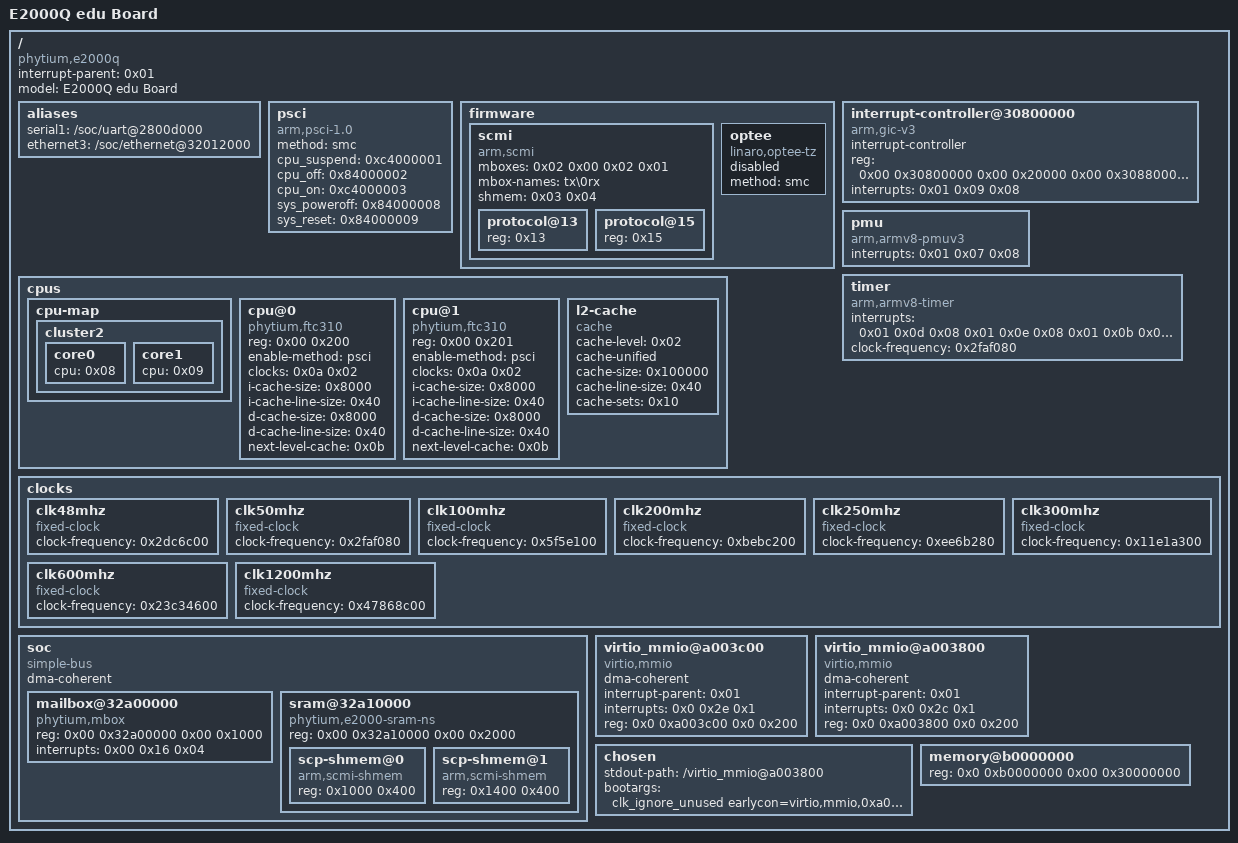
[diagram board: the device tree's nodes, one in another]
/dts-v1/;

/memreserve/	0x0000000080000000 0x0000000000010000;
/ {
	compatible = "phytium,e2000q";
	interrupt-parent = <0x01>;
	#address-cells = <0x02>;
	#size-cells = <0x02>;
	model = "E2000Q edu Board";

	aliases {
		serial1 = "/soc/uart@2800d000";
		ethernet3 = "/soc/ethernet@32012000";
	};

	psci {
		compatible = "arm,psci-1.0";
		method = "smc";
		cpu_suspend = <0xc4000001>;
		cpu_off = <0x84000002>;
		cpu_on = <0xc4000003>;
		sys_poweroff = <0x84000008>;
		sys_reset = <0x84000009>;
	};

	firmware {

		scmi {
			compatible = "arm,scmi";
			mboxes = <0x02 0x00 0x02 0x01>;
			mbox-names = "tx\0rx";
			shmem = <0x03 0x04>;
			#address-cells = <0x01>;
			#size-cells = <0x00>;

			protocol@13 {
				reg = <0x13>;
				#clock-cells = <0x01>;
				phandle = <0x0a>;
			};

			protocol@15 {
				reg = <0x15>;
				#thermal-sensor-cells = <0x01>;
				phandle = <0x05>;
			};
		};

		optee {
			compatible = "linaro,optee-tz";
			method = "smc";
			status = "disabled";
		};
	};

	cpus {
		#address-cells = <0x02>;
		#size-cells = <0x00>;

		cpu-map {

			// cluster0 {

			// 	core0 {
			// 		cpu = <0x06>;
			// 	};
			// };

			// cluster1 {

			// 	core0 {
			// 		cpu = <0x07>;
			// 	};
			// };

			cluster2 {

				core0 {
					cpu = <0x08>;
				};

				core1 {
					cpu = <0x09>;
				};
			};
		};
		// cpu@100 {
		// 	device_type = "cpu";
		// 	compatible = "phytium,ftc664\0arm,armv8";
		// 	reg = <0x00 0x00>;
		// 	enable-method = "psci";
		// 	clocks = <0x0a 0x00>;
		// 	i-cache-size = <0xc000>;
		// 	i-cache-line-size = <0x40>;
		// 	d-cache-size = <0x8000>;
		// 	d-cache-line-size = <0x40>;
		// 	next-level-cache = <0x0b>;
		// 	phandle = <0x06>;
		// };

		// cpu@101 {
		// 	device_type = "cpu";
		// 	compatible = "phytium,ftc664\0arm,armv8";
		// 	reg = <0x00 0x100>;
		// 	enable-method = "psci";
		// 	clocks = <0x0a 0x01>;
		// 	i-cache-size = <0xc000>;
		// 	i-cache-line-size = <0x40>;
		// 	d-cache-size = <0x8000>;
		// 	d-cache-line-size = <0x40>;
		// 	next-level-cache = <0x0b>;
		// 	phandle = <0x07>;
		// };
		cpu@0 {
			device_type = "cpu";
			compatible = "phytium,ftc310\0arm,armv8";
			reg = <0x00 0x200>;
			enable-method = "psci";
			clocks = <0x0a 0x02>;
			i-cache-size = <0x8000>;
			i-cache-line-size = <0x40>;
			d-cache-size = <0x8000>;
			d-cache-line-size = <0x40>;
			next-level-cache = <0x0b>;
			phandle = <0x08>;
		};
		cpu@1 {
			device_type = "cpu";
			compatible = "phytium,ftc310\0arm,armv8";
			reg = <0x00 0x201>;
			enable-method = "psci";
			clocks = <0x0a 0x02>;
			i-cache-size = <0x8000>;
			i-cache-line-size = <0x40>;
			d-cache-size = <0x8000>;
			d-cache-line-size = <0x40>;
			next-level-cache = <0x0b>;
			phandle = <0x09>;
		};

		l2-cache {
			compatible = "cache";
			cache-level = <0x02>;
			cache-unified;
			cache-size = <0x100000>;
			cache-line-size = <0x40>;
			cache-sets = <0x10>;
			phandle = <0x0b>;
		};
	};

	interrupt-controller@30800000 {
		compatible = "arm,gic-v3";
		#interrupt-cells = <0x03>;
		#address-cells = <0x02>;
		#size-cells = <0x02>;
		ranges;
		interrupt-controller;
		reg = <0x00 0x30800000 0x00 0x20000 0x00 0x30880000 0x00 0x80000 0x00 0x30840000 0x00 0x10000 0x00 0x30850000 0x00 0x10000 0x00 0x30860000 0x00 0x10000>;
		interrupts = <0x01 0x09 0x08>;
		phandle = <0x01>;

		// gic-its@30820000 {
		// 	compatible = "arm,gic-v3-its";
		// 	msi-controller;
		// 	reg = <0x00 0x30820000 0x00 0x20000>;
		// 	phandle = <0x10>;
		// };
	};

	pmu {
		compatible = "arm,armv8-pmuv3";
		interrupts = <0x01 0x07 0x08>;
	};

	timer {
		compatible = "arm,armv8-timer";
		interrupts = <0x01 0x0d 0x08 0x01 0x0e 0x08 0x01 0x0b 0x08 0x01 0x0a 0x08>;
		clock-frequency = <0x2faf080>;
	};

	clocks {
		#address-cells = <0x02>;
		#size-cells = <0x02>;
		ranges;

		clk48mhz {
			compatible = "fixed-clock";
			#clock-cells = <0x00>;
			clock-frequency = <0x2dc6c00>;
			phandle = <0x14>;
		};

		clk50mhz {
			compatible = "fixed-clock";
			#clock-cells = <0x00>;
			clock-frequency = <0x2faf080>;
			phandle = <0x0f>;
		};

		clk100mhz {
			compatible = "fixed-clock";
			#clock-cells = <0x00>;
			clock-frequency = <0x5f5e100>;
			phandle = <0x0e>;
		};

		clk200mhz {
			compatible = "fixed-clock";
			#clock-cells = <0x00>;
			clock-frequency = <0xbebc200>;
			phandle = <0x12>;
		};

		clk250mhz {
			compatible = "fixed-clock";
			#clock-cells = <0x00>;
			clock-frequency = <0xee6b280>;
			phandle = <0x13>;
		};

		clk300mhz {
			compatible = "fixed-clock";
			#clock-cells = <0x00>;
			clock-frequency = <0x11e1a300>;
		};

		clk600mhz {
			compatible = "fixed-clock";
			#clock-cells = <0x00>;
			clock-frequency = <0x23c34600>;
			phandle = <0x0d>;
		};

		clk1200mhz {
			compatible = "fixed-clock";
			#clock-cells = <0x00>;
			clock-frequency = <0x47868c00>;
			phandle = <0x0c>;
		};
	};


	soc {
		compatible = "simple-bus";
		#address-cells = <0x02>;
		#size-cells = <0x02>;
		dma-coherent;
		ranges;

		// uart@2800d000 {
		// 	compatible = "arm,pl011\0arm,primecell";
		// 	reg = <0x00 0x2800d000 0x00 0x1000>;
		// 	interrupts = <0x00 0x54 0x04>;
		// 	clocks = <0x0e 0x0e>;
		// 	clock-names = "uartclk\0apb_pclk";
		// 	status = "okay";
		// };


		mailbox@32a00000 {
			compatible = "phytium,mbox";
			reg = <0x00 0x32a00000 0x00 0x1000>;
			interrupts = <0x00 0x16 0x04>;
			#mbox-cells = <0x01>;
			phandle = <0x02>;
		};

		sram@32a10000 {
			compatible = "phytium,e2000-sram-ns\0mmio-sram";
			reg = <0x00 0x32a10000 0x00 0x2000>;
			#address-cells = <0x01>;
			#size-cells = <0x01>;
			ranges = <0x00 0x00 0x32a10000 0x2000>;

			scp-shmem@0 {
				compatible = "arm,scmi-shmem";
				reg = <0x1000 0x400>;
				phandle = <0x04>;
			};

			scp-shmem@1 {
				compatible = "arm,scmi-shmem";
				reg = <0x1400 0x400>;
				phandle = <0x03>;
			};
		};
	};
	// virtio blk
	virtio_mmio@a003c00 {
		dma-coherent;
		interrupt-parent = <0x01>;
		interrupts = <0x0 0x2e 0x1>;
		reg = <0x0 0xa003c00 0x0 0x200>;
		compatible = "virtio,mmio";
	};
	//virtio serial
	virtio_mmio@a003800 {
		dma-coherent;
		interrupt-parent = <0x01>;
		interrupts = <0x0 0x2c 0x1>;
		reg = <0x0 0xa003800 0x0 0x200>;
		compatible = "virtio,mmio";
	};

	chosen {
		stdout-path = "/virtio_mmio@a003800";
		bootargs = "clk_ignore_unused earlycon=virtio,mmio,0xa003800 console=hvc0 root=/dev/vda rootwait rw init=/bin/sh";

	};

	memory@b0000000 {
		device_type = "memory";
		reg = <0x0 0xb0000000 0x00 0x30000000>;
	};

};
